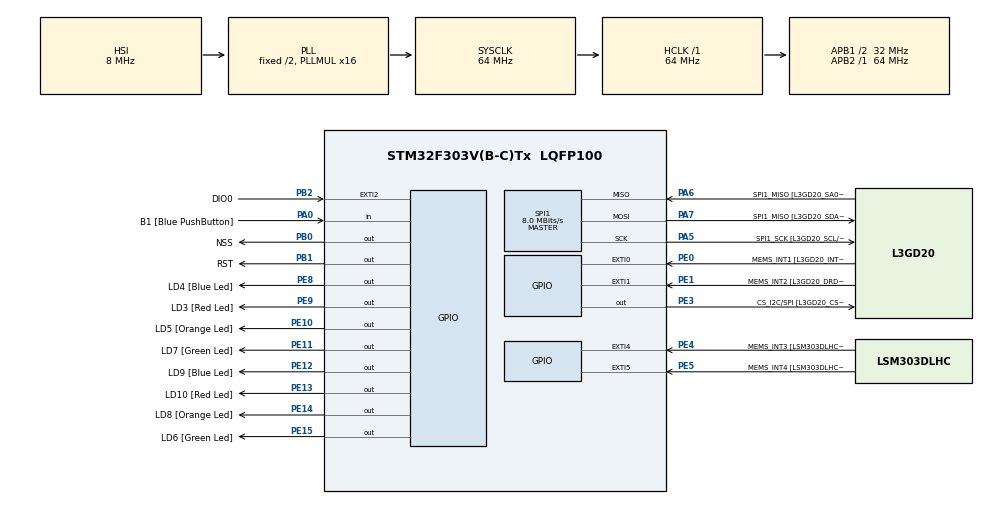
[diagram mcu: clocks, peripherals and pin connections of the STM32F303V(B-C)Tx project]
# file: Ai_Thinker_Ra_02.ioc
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Mcu.Family=STM32F3
Mcu.Name=STM32F303V(B-C)Tx
Mcu.Package=LQFP100
NVIC.PriorityGroup=NVIC_PRIORITYGROUP_0
PA0.GPIO_Label=B1 [Blue PushButton]
PA0.GPIO_Mode=GPIO_MODE_INPUT
PA0.GPIO_PuPd=GPIO_NOPULL
PA0.Signal=GPIO_Input
PA11.GPIO_Label=DM
PA11.Signal=USB_DM
PA12.GPIO_Label=DP
PA12.Signal=USB_DP
PA13.GPIO_Label=SWDIO
PA13.Mode=Serial_Wire
PA13.Signal=SYS_JTMS-SWDIO
PA14.GPIO_Label=SWCLK
PA14.Mode=Serial_Wire
PA14.Signal=SYS_JTCK-SWCLK
PA5.GPIO_Label=SPI1_SCK [L3GD20_SCL/SPC]
PA5.GPIO_Mode=GPIO_MODE_AF_PP
PA5.GPIO_PuPd=GPIO_NOPULL
PA5.GPIO_Speed=GPIO_SPEED_FREQ_LOW
PA5.Mode=Full_Duplex_Master
PA5.Signal=SPI1_SCK
PA6.GPIO_Label=SPI1_MISO [L3GD20_SA0/SDO]
PA6.GPIO_Mode=GPIO_MODE_AF_PP
PA6.GPIO_PuPd=GPIO_NOPULL
PA6.GPIO_Speed=GPIO_SPEED_FREQ_LOW
PA6.Mode=Full_Duplex_Master
PA6.Signal=SPI1_MISO
PA7.GPIO_Label=SPI1_MISO [L3GD20_SDA/SDI/SDO]
PA7.GPIO_Mode=GPIO_MODE_AF_PP
PA7.GPIO_PuPd=GPIO_NOPULL
PA7.GPIO_Speed=GPIO_SPEED_FREQ_LOW
PA7.Mode=Full_Duplex_Master
PA7.Signal=SPI1_MOSI
PB0.GPIO_Label=NSS
PB0.PinState=GPIO_PIN_SET
PB0.Signal=GPIO_Output
PB1.GPIO_Label=RST
PB1.PinState=GPIO_PIN_SET
PB1.Signal=GPIO_Output
PB2.GPIO_Label=DIO0
PB2.Signal=GPXTI2
PB3.GPIO_Label=SWO
PB3.Signal=SYS_JTDO-TRACESWO
PB6.GPIO_FM6=__NULL
PB6.GPIO_Label=I2C1_SCL [LSM303DLHC_SCL]
PB6.GPIO_Mode=GPIO_MODE_AF_OD
PB6.GPIO_PuPd=GPIO_NOPULL
PB6.GPIO_Speed=GPIO_SPEED_FREQ_LOW
PB6.Signal=I2C1_SCL
PB7.GPIO_FM7=__NULL
PB7.GPIO_Label=I2C1_SDA [LSM303DLHC_SDA]
PB7.GPIO_Mode=GPIO_MODE_AF_OD
PB7.GPIO_PuPd=GPIO_NOPULL
PB7.GPIO_Speed=GPIO_SPEED_FREQ_LOW
PB7.Signal=I2C1_SDA
PC14-OSC32_IN.GPIO_Label=OSC32_IN
PC14-OSC32_IN.Signal=RCC_OSC32_IN
PC15-OSC32_OUT.GPIO_Label=OSC32_OUT
PC15-OSC32_OUT.Signal=RCC_OSC32_OUT
PE0.GPIO_Label=MEMS_INT1 [L3GD20_INT1]
PE0.GPIO_ModeDefaultEXTI=GPIO_MODE_EVT_RISING
PE0.GPIO_PuPd=GPIO_NOPULL
PE0.Signal=GPXTI0
PE1.GPIO_Label=MEMS_INT2 [L3GD20_DRDY/INT2]
PE1.GPIO_ModeDefaultEXTI=GPIO_MODE_EVT_RISING
PE1.GPIO_PuPd=GPIO_NOPULL
PE1.Signal=GPXTI1
PE10.GPIO_Label=LD5 [Orange Led]
PE10.GPIO_ModeDefaultOutputPP=GPIO_MODE_OUTPUT_PP
PE10.GPIO_PuPd=GPIO_NOPULL
PE10.GPIO_Speed=GPIO_SPEED_FREQ_LOW
PE10.Signal=GPIO_Output
PE11.GPIO_Label=LD7 [Green Led]
PE11.GPIO_ModeDefaultOutputPP=GPIO_MODE_OUTPUT_PP
PE11.GPIO_PuPd=GPIO_NOPULL
PE11.GPIO_Speed=GPIO_SPEED_FREQ_LOW
PE11.Signal=GPIO_Output
PE12.GPIO_Label=LD9 [Blue Led]
PE12.GPIO_ModeDefaultOutputPP=GPIO_MODE_OUTPUT_PP
PE12.GPIO_PuPd=GPIO_NOPULL
PE12.GPIO_Speed=GPIO_SPEED_FREQ_LOW
PE12.Signal=GPIO_Output
PE13.GPIO_Label=LD10 [Red Led]
PE13.GPIO_ModeDefaultOutputPP=GPIO_MODE_OUTPUT_PP
PE13.GPIO_PuPd=GPIO_NOPULL
PE13.GPIO_Speed=GPIO_SPEED_FREQ_LOW
PE13.Signal=GPIO_Output
PE14.GPIO_Label=LD8 [Orange Led]
PE14.GPIO_ModeDefaultOutputPP=GPIO_MODE_OUTPUT_PP
PE14.GPIO_PuPd=GPIO_NOPULL
PE14.GPIO_Speed=GPIO_SPEED_FREQ_LOW
PE14.Signal=GPIO_Output
PE15.GPIO_Label=LD6 [Green Led]
PE15.GPIO_ModeDefaultOutputPP=GPIO_MODE_OUTPUT_PP
PE15.GPIO_PuPd=GPIO_NOPULL
PE15.GPIO_Speed=GPIO_SPEED_FREQ_LOW
PE15.Signal=GPIO_Output
PE3.GPIO_Label=CS_I2C/SPI [L3GD20_CS_I2C/SPI]
PE3.GPIO_ModeDefaultOutputPP=GPIO_MODE_OUTPUT_PP
PE3.GPIO_PuPd=GPIO_NOPULL
PE3.GPIO_Speed=GPIO_SPEED_FREQ_LOW
PE3.Signal=GPIO_Output
PE4.GPIO_Label=MEMS_INT3 [LSM303DLHC_INT1]
PE4.GPIO_ModeDefaultEXTI=GPIO_MODE_EVT_RISING
PE4.GPIO_PuPd=GPIO_NOPULL
PE4.Signal=GPXTI4
PE5.GPIO_Label=MEMS_INT4 [LSM303DLHC_INT2]
PE5.GPIO_ModeDefaultEXTI=GPIO_MODE_EVT_RISING
PE5.GPIO_PuPd=GPIO_NOPULL
PE5.Signal=GPXTI5
PE8.GPIO_Label=LD4 [Blue Led]
PE8.GPIO_ModeDefaultOutputPP=GPIO_MODE_OUTPUT_PP
PE8.GPIO_PuPd=GPIO_NOPULL
PE8.GPIO_Speed=GPIO_SPEED_FREQ_LOW
PE8.Signal=GPIO_Output
PE9.GPIO_Label=LD3 [Red Led]
PE9.GPIO_ModeDefaultOutputPP=GPIO_MODE_OUTPUT_PP
PE9.GPIO_PuPd=GPIO_NOPULL
PE9.GPIO_Speed=GPIO_SPEED_FREQ_LOW
PE9.Signal=GPIO_Output
PF0-OSC_IN.GPIO_Label=OSC_IN
PF0-OSC_IN.Signal=RCC_OSC_IN
PF1-OSC_OUT.GPIO_Label=OSC_OUT
PF1-OSC_OUT.Signal=RCC_OSC_OUT
ProjectManager.HeapSize=0x200
ProjectManager.StackSize=0x400
ProjectManager.TargetToolchain=STM32CubeIDE
RCC.AHBFreq_Value=64000000
RCC.APB1CLKDivider=RCC_HCLK_DIV2
RCC.APB1Freq_Value=32000000
RCC.APB1TimFreq_Value=64000000
RCC.APB2Freq_Value=64000000
RCC.APB2TimFreq_Value=64000000
RCC.CortexFreq_Value=64000000
RCC.HCLKFreq_Value=64000000
RCC.HSE_VALUE=8000000
RCC.HSI_VALUE=8000000
RCC.LSE_VALUE=32768
RCC.PLLMUL=RCC_PLL_MUL16
RCC.SYSCLKFreq_VALUE=64000000
RCC.SYSCLKSourceVirtual=RCC_SYSCLKSOURCE_PLLCLK
RCC.USBFreq_Value=64000000
SPI1.BaudRatePrescaler=SPI_BAUDRATEPRESCALER_8
SPI1.CalculateBaudRate=8.0 MBits/s
SPI1.DataSize=SPI_DATASIZE_8BIT
SPI1.Direction=SPI_DIRECTION_2LINES
SPI1.Mode=SPI_MODE_MASTER
SPI1.VirtualType=VM_MASTER
board=STM32F3DISCOVERY

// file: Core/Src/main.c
/* USER CODE BEGIN Header */
/**
  ******************************************************************************
  * @file           : main.c
  * @brief          : Main program body
  ******************************************************************************
  * @attention
  *
  * <h2><center>&copy; Copyright (c) 2021 STMicroelectronics.
  * All rights reserved.</center></h2>
  *
  * This software component is licensed by ST under BSD 3-Clause license,
  * the "License"; You may not use this file except in compliance with the
  * License. You may obtain a copy of the License at:
  *                        opensource.org/licenses/BSD-3-Clause
  *
  ******************************************************************************
  */
/* USER CODE END Header */
#include "main.h"
#include "spi.h"
#include "gpio.h"

/* USER CODE BEGIN Includes */

#include "LoRa.h"
/* USER CODE END Includes */

/* USER CODE BEGIN PV */
 LoRa myLoRa;
 uint8_t LoRa_status;
/* USER CODE END PV */

void SystemClock_Config(void);

int main(void)
{

  /* MCU Configuration--------------------------------------------------------*/

  /* Reset of all peripherals, Initializes the Flash interface and the Systick. */
  HAL_Init();

  /* Configure the system clock */
  SystemClock_Config();

  /* Initialize all configured peripherals */
  MX_GPIO_Init();
  MX_SPI1_Init();
  /* USER CODE BEGIN 2 */
  myLoRa = newLoRa();

  myLoRa.CS_port         = NSS_GPIO_Port;
  myLoRa.CS_pin          = NSS_Pin;
  myLoRa.reset_port      = RST_GPIO_Port;
  myLoRa.reset_pin       = RST_Pin;
  myLoRa.DIO0_port       = DIO0_GPIO_Port;
  myLoRa.DIO0_pin        = DIO0_Pin;
  myLoRa.hSPIx           = &hspi1;

  if(LoRa_init(&myLoRa) == LORA_OK) {
	  LoRa_status = 1;
  }

  /* USER CODE END 2 */

  /* Infinite loop */
  while (1)
  {

  }
}

void SystemClock_Config(void)
{
  RCC_OscInitTypeDef RCC_OscInitStruct = {0};
  RCC_ClkInitTypeDef RCC_ClkInitStruct = {0};

  /** Initializes the RCC Oscillators according to the specified parameters
  * in the RCC_OscInitTypeDef structure.
  */
  RCC_OscInitStruct.OscillatorType = RCC_OSCILLATORTYPE_HSI;
  RCC_OscInitStruct.HSIState = RCC_HSI_ON;
  RCC_OscInitStruct.HSICalibrationValue = RCC_HSICALIBRATION_DEFAULT;
  RCC_OscInitStruct.PLL.PLLState = RCC_PLL_ON;
  RCC_OscInitStruct.PLL.PLLSource = RCC_PLLSOURCE_HSI;
  RCC_OscInitStruct.PLL.PLLMUL = RCC_PLL_MUL16;
  if (HAL_RCC_OscConfig(&RCC_OscInitStruct) != HAL_OK)
  {
    Error_Handler();
  }
  /** Initializes the CPU, AHB and APB buses clocks
  */
  RCC_ClkInitStruct.ClockType = RCC_CLOCKTYPE_HCLK|RCC_CLOCKTYPE_SYSCLK
                              |RCC_CLOCKTYPE_PCLK1|RCC_CLOCKTYPE_PCLK2;
  RCC_ClkInitStruct.SYSCLKSource = RCC_SYSCLKSOURCE_PLLCLK;
  RCC_ClkInitStruct.AHBCLKDivider = RCC_SYSCLK_DIV1;
  RCC_ClkInitStruct.APB1CLKDivider = RCC_HCLK_DIV2;
  RCC_ClkInitStruct.APB2CLKDivider = RCC_HCLK_DIV1;

  if (HAL_RCC_ClockConfig(&RCC_ClkInitStruct, FLASH_LATENCY_2) != HAL_OK)
  {
    Error_Handler();
  }
}

void Error_Handler(void)
{
  __disable_irq();
  while (1)
  {
  }
}

/************************ (C) COPYRIGHT STMicroelectronics *****END OF FILE****/
